# ATSAMG55J register map
Vendor: Microchip Technology; Series: SAMG55; File version: 0
CPU: CM4 r0p1, little endian, MPU, FPU, 4 interrupt priority bits
Registers are 32-bit, read-write, reset 0x0 unless marked. A register's access mark holds for its fields unless they carry their own. Offsets are from the block's base; [hi:lo] are bit positions; {n}, {i} and the like mark numbered series.

## CMCC — Cortex-M Cache Controller
Base 0x4003C000; register names take the prefix CMCC_
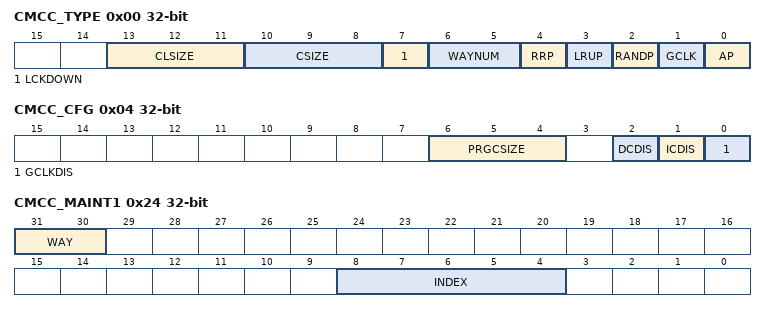
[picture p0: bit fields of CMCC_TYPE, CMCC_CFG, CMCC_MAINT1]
0x00 CMCC_TYPE ro — Cache Controller Type Register
  [13:11] CLSIZE — Cache LIne Size
    0=CLSIZE_1KB (Cache line size is 4 bytes); 1=CLSIZE_2KB (Cache line size is 8 bytes); 2=CLSIZE_4KB (Cache line size is 16 bytes); 3=CLSIZE_8KB (Cache line size is 32 bytes)
  [10:8] CSIZE — Data Cache Size
    0=CSIZE_1KB (Data cache size is 1 Kbyte); 1=CSIZE_2KB (Data cache size is 2 Kbytes); 2=CSIZE_4KB (Data cache size is 4 Kbytes); 3=CSIZE_8KB (Data cache size is 8 Kbytes)
  [7] LCKDOWN — Lockdown Supported
  [6:5] WAYNUM — Number of Ways
    0=DMAPPED (Direct Mapped Cache); 1=ARCH2WAY (2-way set associative); 2=ARCH4WAY (4-way set associative); 3=ARCH8WAY (8-way set associative)
  [4] RRP — Random Selection Policy Supported
  [3] LRUP — Least Recently Used Policy Supported
  [2] RANDP — Random Selection Policy Supported
  [1] GCLK — Dynamic Clock Gating Supported
  [0] AP — Access Port Access Allowed
0x04 CMCC_CFG — Cache Controller Configuration Register
  [6:4] PRGCSIZE
  [2] DCDIS
  [1] ICDIS
  [0] GCLKDIS — Disable Clock Gating
0x08 CMCC_CTRL wo — Cache Controller Control Register
  [0] CEN — Cache Controller Enable
0x0C CMCC_SR ro — Cache Controller Status Register
  [0] CSTS — Cache Controller Status
0x20 CMCC_MAINT0 wo — Cache Controller Maintenance Register 0
  [0] INVALL — Cache Controller Invalidate All
0x24 CMCC_MAINT1 wo — Cache Controller Maintenance Register 1
  [31:30] WAY — Invalidate Way
    {v}=Way {v} is selection for index invalidation (v=0..3)
  [8:4] INDEX — Invalidate Index
0x28 CMCC_MCFG — Cache Controller Monitor Configuration Register
  [1:0] MODE — Cache Controller Monitor Counter Mode
    0=CYCLE_COUNT (Cycle counter); 1=IHIT_COUNT (Instruction hit counter); 2=DHIT_COUNT (Data hit counter)
0x2C CMCC_MEN — Cache Controller Monitor Enable Register
  [0] MENABLE — Cache Controller Monitor Enable
0x30 CMCC_MCTRL wo — Cache Controller Monitor Control Register
  [0] SWRST — Monitor
0x34 CMCC_MSR ro — Cache Controller Monitor Status Register
  [31:0] EVENT_CNT — Monitor Event Counter

## CRCCU — Cyclic Redundancy Check Calculation Unit
Base 0x40048000; register names take the prefix CRCCU_
0x00 CRCCU_DSCR — CRCCU Descriptor Base Register
  [31:9] DSCR — Descriptor Base Address
0x08 CRCCU_DMA_EN wo — CRCCU DMA Enable Register
  [0] DMAEN — DMA Enable
0x0C CRCCU_DMA_DIS wo — CRCCU DMA Disable Register
  [0] DMADIS — DMA Disable
0x10 CRCCU_DMA_SR ro — CRCCU DMA Status Register
  [0] DMASR — DMA Status
0x14 CRCCU_DMA_IER wo — CRCCU DMA Interrupt Enable Register
  [0] DMAIER — Interrupt Enable
0x18 CRCCU_DMA_IDR wo — CRCCU DMA Interrupt Disable Register
  [0] DMAIDR — Interrupt Disable
0x1C CRCCU_DMA_IMR ro — CRCCU DMA Interrupt Mask Register
  [0] DMAIMR — Interrupt Mask
0x20 CRCCU_DMA_ISR ro — CRCCU DMA Interrupt Status Register
  [0] DMAISR — Interrupt Status
0x34 CRCCU_CR wo — CRCCU Control Register
  [0] RESET — CRC Computation Reset
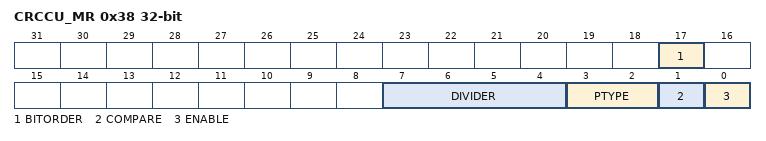
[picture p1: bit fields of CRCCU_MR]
0x38 CRCCU_MR — CRCCU Mode Register
  [17] BITORDER — Precomputation Bit Swap Operation of the CRC
    0=MSBFIRST (CRC computation is performed from the most significant bit to the least significant bit); 1=LSBFIRST (CRC computation is performed from the least significant bit to the most significant bit)
  [7:4] DIVIDER — Request Divider
  [3:2] PTYPE — Primitive Polynomial
    0=CCITT8023 (Polynom 0x04C11DB7); 1=CASTAGNOLI (Polynom 0x1EDC6F41); 2=CCITT16 (Polynom 0x1021)
  [1] COMPARE — CRC Compare
  [0] ENABLE — CRC Enable
0x3C CRCCU_SR ro — CRCCU Status Register
  [31:0] CRC — Cyclic Redundancy Check Value
0x40 CRCCU_IER wo — CRCCU Interrupt Enable Register
  [0] ERRIER — CRC Error Interrupt Enable
0x44 CRCCU_IDR wo — CRCCU Interrupt Disable Register
  [0] ERRIDR — CRC Error Interrupt Disable
0x48 CRCCU_IMR ro — CRCCU Interrupt Mask Register
  [0] ERRIMR — CRC Error Interrupt Mask
0x4C CRCCU_ISR ro — CRCCU Interrupt Status Register
  [0] ERRISR — CRC Error Interrupt Status

## Notices in the file
Copyright (c) 2017 Microchip Technology Inc.
SPDX-License-Identifier: Apache-2.0
Licensed under the Apache License, Version 2.0 (the "License");
you may not use this file except in compliance with the License.
You may obtain a copy of the License at
http://www.apache.org/licenses/LICENSE-2.0
Unless required by applicable law or agreed to in writing, software
distributed under the License is distributed on an "AS IS" BASIS,
WITHOUT WARRANTIES OR CONDITIONS OF ANY KIND, either express or implied.
See the License for the specific language governing permissions and
limitations under the License.
